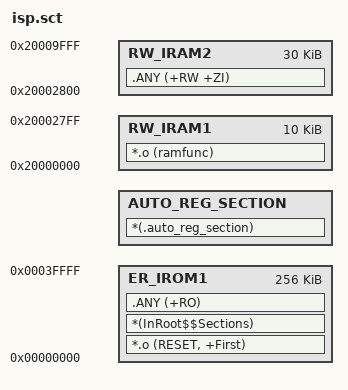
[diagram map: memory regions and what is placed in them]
; *************************************************************
; *** Scatter-Loading Description File generated by uVision ***
; *************************************************************


LR_IROM1 0x00000000 0x00040000  {    ; load region size_region
  ER_IROM1 0x00000000 0x00040000  {  ; load address = execution address
   *.o (RESET, +First)
   *(InRoot$$Sections)
   .ANY (+RO)
  }
  AUTO_REG_SECTION +0 
  {
        *(.auto_reg_section)
  }
  RW_IRAM1 0x20000000 0x00002800  {  ; RW data
     *.o (ramfunc)
  }
  RW_IRAM2 0x20002800 0x00007800  {  ; RW data
   .ANY (+RW +ZI)
  }
}

